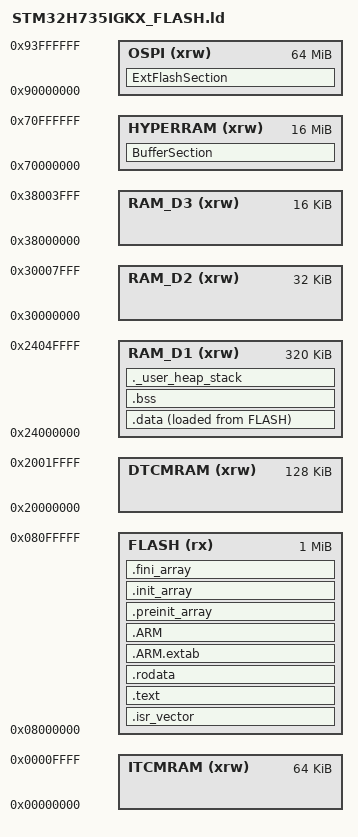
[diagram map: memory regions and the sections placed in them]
/**
 ******************************************************************************
 * @file      LinkerScript.ld
 * @author    Auto-generated by STM32CubeIDE
 * @brief     Linker script for STM32H735IGKx Device from STM32H7 series
 *                      1024Kbytes FLASH
 *                      128Kbytes DTCMRAM
 *                      64Kbytes ITCMRAM
 *                      320Kbytes RAM_D1
 *                      32Kbytes RAM_D2
 *                      16Kbytes RAM_D3
 *
 *            Set heap size, stack size and stack location according
 *            to application requirements.
 *
 *            Set memory bank area and size if external memory is used
 ******************************************************************************
 * @attention
 *
 * <h2><center>&copy; Copyright (c) 2020 STMicroelectronics.
 * All rights reserved.</center></h2>
 *
 * This software component is licensed by ST under BSD 3-Clause license,
 * the "License"; You may not use this file except in compliance with the
 * License. You may obtain a copy of the License at:
 *                        opensource.org/licenses/BSD-3-Clause
 *
 ******************************************************************************
 */

/* Entry Point */
ENTRY(Reset_Handler)

/* Highest address of the user mode stack */
_estack = ORIGIN(RAM_D1) + LENGTH(RAM_D1);	/* end of "RAM_D1" Ram type memory */

_Min_Heap_Size = 0x1000;	/* required amount of heap  */
_Min_Stack_Size = 0x1000;	/* required amount of stack */

/* Memories definition */
MEMORY
{
  DTCMRAM    (xrw)    : ORIGIN = 0x20000000,   LENGTH = 128K
  ITCMRAM    (xrw)    : ORIGIN = 0x00000000,   LENGTH = 64K
  RAM_D1     (xrw)    : ORIGIN = 0x24000000,   LENGTH = 320K
  RAM_D2     (xrw)    : ORIGIN = 0x30000000,   LENGTH = 32K
  RAM_D3     (xrw)    : ORIGIN = 0x38000000,   LENGTH = 16K
  FLASH      (rx)     : ORIGIN = 0x8000000,    LENGTH = 1024K
  OSPI	     (xrw)    : ORIGIN = 0x90000000,   LENGTH = 64M
  HYPERRAM   (xrw)    : ORIGIN = 0x70000000,   LENGTH = 16M
}

/* Sections */
SECTIONS
{
  /* The startup code into "FLASH" Rom type memory */
  .isr_vector :
  {
    . = ALIGN(4);
    KEEP(*(.isr_vector)) /* Startup code */
    . = ALIGN(4);
  } >FLASH

  /* The program code and other data into "FLASH" Rom type memory */
  .text :
  {
    . = ALIGN(4);
    *(.text)           /* .text sections (code) */
    *(.text*)          /* .text* sections (code) */
    *(.glue_7)         /* glue arm to thumb code */
    *(.glue_7t)        /* glue thumb to arm code */
    *(.eh_frame)

    KEEP (*(.init))
    KEEP (*(.fini))

    . = ALIGN(4);
    _etext = .;        /* define a global symbols at end of code */
  } >FLASH

  /* Constant data into "FLASH" Rom type memory */
  .rodata :
  {
    . = ALIGN(4);
    *(.rodata)         /* .rodata sections (constants, strings, etc.) */
    *(.rodata*)        /* .rodata* sections (constants, strings, etc.) */
    . = ALIGN(4);
  } >FLASH

  .ARM.extab   : { 
    . = ALIGN(4);
    *(.ARM.extab* .gnu.linkonce.armextab.*)
    . = ALIGN(4);
  } >FLASH
  
  .ARM : {
    . = ALIGN(4);
    __exidx_start = .;
    *(.ARM.exidx*)
    __exidx_end = .;
    . = ALIGN(4);
  } >FLASH

  .preinit_array     :
  {
    . = ALIGN(4);
    PROVIDE_HIDDEN (__preinit_array_start = .);
    KEEP (*(.preinit_array*))
    PROVIDE_HIDDEN (__preinit_array_end = .);
    . = ALIGN(4);
  } >FLASH
  
  .init_array :
  {
    . = ALIGN(4);
    PROVIDE_HIDDEN (__init_array_start = .);
    KEEP (*(SORT(.init_array.*)))
    KEEP (*(.init_array*))
    PROVIDE_HIDDEN (__init_array_end = .);
    . = ALIGN(4);
  } >FLASH
  
  .fini_array :
  {
    . = ALIGN(4);
    PROVIDE_HIDDEN (__fini_array_start = .);
    KEEP (*(SORT(.fini_array.*)))
    KEEP (*(.fini_array*))
    PROVIDE_HIDDEN (__fini_array_end = .);
    . = ALIGN(4);
  } >FLASH

  /* Used by the startup to initialize data */
  _sidata = LOADADDR(.data);

  /* Initialized data sections into "RAM_D1" Ram type memory */
  .data : 
  {
    . = ALIGN(4);
    _sdata = .;        /* create a global symbol at data start */
    *(.data)           /* .data sections */
    *(.data*)          /* .data* sections */

    . = ALIGN(4);
    _edata = .;        /* define a global symbol at data end */
    
  } >RAM_D1 AT> FLASH

  /* Uninitialized data section into "RAM_D1" Ram type memory */
  . = ALIGN(4);
  .bss :
  {
    /* This is used by the startup in order to initialize the .bss section */
    _sbss = .;         /* define a global symbol at bss start */
    __bss_start__ = _sbss;
    *(.bss)
    *(.bss*)
    *(COMMON)

    . = ALIGN(4);
    _ebss = .;         /* define a global symbol at bss end */
    __bss_end__ = _ebss;
  } >RAM_D1

  /* User_heap_stack section, used to check that there is enough "RAM_D1" Ram  type memory left */
  ._user_heap_stack :
  {
    . = ALIGN(8);
    PROVIDE ( end = . );
    PROVIDE ( _end = . );
    . = . + _Min_Heap_Size;
    . = . + _Min_Stack_Size;
    . = ALIGN(8);
  } >RAM_D1

  /* Remove information from the compiler libraries */
  /DISCARD/ :
  {
    libc.a ( * )
    libm.a ( * )
    libgcc.a ( * )
  }

  .ARM.attributes 0 : { *(.ARM.attributes) }
/*
  FontFlashSection :
  {
    *(FontFlashSection FontFlashSection.*)
    *(.gnu.linkonce.r.*)
    . = ALIGN(0x4);
  } >OSPI

  TextFlashSection :
  {
    *(TextFlashSection TextFlashSection.*)
    *(.gnu.linkonce.r.*)
    . = ALIGN(0x4);
  } >OSPI
*/
  ExtFlashSection :
  {
    *(ExtFlashSection ExtFlashSection.*)
    *(.gnu.linkonce.r.*)
    . = ALIGN(0x4);
  } >OSPI
  
  BufferSection (NOLOAD) :
  {
	*(TouchGFX_Framebuffer TouchGFX_Framebuffer.*)
    *(.gnu.linkonce.r.*)
    . = ALIGN(0x4);
	
	*(Video_RGB_Buffer Video_RGB_Buffer.*)
    *(.gnu.linkonce.r.*)
    . = ALIGN(0x4);
        
    *(image_abs_detection_r_buf image_abs_detection_r_buf.*)
    *(.gnu.linkonce.r.*)
    . = ALIGN(0x4);
    
	*(image_abs_detection_w_buf image_abs_detection_w_buf.*)
	*(.gnu.linkonce.r.*)
    . = ALIGN(0x4);
    
    *(image_fuelicon_r_buf image_fuelicon_r_buf.*)
	*(.gnu.linkonce.r.*)
    . = ALIGN(0x4);
    
    *(image_fuelicon_w_buf image_fuelicon_w_buf.*)
	*(.gnu.linkonce.r.*)
    . = ALIGN(0x4);
    
    *(image_doorsicon_r_buf image_doorsicon_r_buf.*)
	*(.gnu.linkonce.r.*)
    . = ALIGN(0x4);
    
    *(image_doorsicon_w_buf image_doorsicon_w_buf.*)
	*(.gnu.linkonce.r.*)
    . = ALIGN(0x4);
    
    *(image_engineoil_r_buf image_engineoil_r_buf.*)
	*(.gnu.linkonce.r.*)
    . = ALIGN(0x4);
    
    *(image_engineoil_w_buf image_engineoil_w_buf.*)
	*(.gnu.linkonce.r.*)
    . = ALIGN(0x4);
    
    *(image_enginewarning_w_buf image_enginewarning_w_buf.*)
	*(.gnu.linkonce.r.*)
    . = ALIGN(0x4);
    
    *(image_enginewarning_y_buf image_enginewarning_y_buf.*)
	*(.gnu.linkonce.r.*)
    . = ALIGN(0x4);
    
    *(image_fuelbar01_buf image_fuelbar01_buf.*)
	*(.gnu.linkonce.r.*)
    . = ALIGN(0x4);
    
    *(image_fuelbar02_buf image_fuelbar02_buf.*)
	*(.gnu.linkonce.r.*)
    . = ALIGN(0x4);
    
    *(image_fuelbar03_buf image_fuelbar03_buf.*)
	*(.gnu.linkonce.r.*)
    . = ALIGN(0x4);
    
    *(image_fuelbar04_buf image_fuelbar04_buf.*)
	*(.gnu.linkonce.r.*)
    . = ALIGN(0x4);
    
    *(image_fuelbar05_buf image_fuelbar05_buf.*)
	*(.gnu.linkonce.r.*)
    . = ALIGN(0x4);
    
    *(image_fuelbar06_buf image_fuelbar06_buf.*)
	*(.gnu.linkonce.r.*)
    . = ALIGN(0x4);
    
    *(image_fuelbar07_buf image_fuelbar07_buf.*)
	*(.gnu.linkonce.r.*)
    . = ALIGN(0x4);
    
    *(image_fuelbar08_buf image_fuelbar08_buf.*)
	*(.gnu.linkonce.r.*)
    . = ALIGN(0x4);
    
    *(image_fuelbar09_buf image_fuelbar09_buf.*)
	*(.gnu.linkonce.r.*)
    . = ALIGN(0x4);
    
    *(image_fuelbar10_buf image_fuelbar10_buf.*)
	*(.gnu.linkonce.r.*)
    . = ALIGN(0x4);
    
     *(image_highbeam_blue_buf image_highbeam_blue_buf.*)
	*(.gnu.linkonce.r.*)
    . = ALIGN(0x4);
    
    *(image_highbeam_wb_buf image_highbeam_wb_buf.*)
	*(.gnu.linkonce.r.*)
    . = ALIGN(0x4);
    
    *(image_highbeam_r_buf image_highbeam_r_buf.*)
	*(.gnu.linkonce.r.*)
    . = ALIGN(0x4);
    
    *(image_highbeam_w_buf image_highbeam_w_buf.*)
	*(.gnu.linkonce.r.*)
    . = ALIGN(0x4);
    
    *(image_hmi_layout1_buf image_hmi_layout1_buf.*)
	*(.gnu.linkonce.r.*)
    . = ALIGN(0x4);
    
    *(image_leftindicator_r_buf image_leftindicator_r_buf.*)
	*(.gnu.linkonce.r.*)
    . = ALIGN(0x4);
    
    *(image_leftindicator_w_buf image_leftindicator_w_buf.*)
	*(.gnu.linkonce.r.*)
    . = ALIGN(0x4);
    
    *(image_lowbatteryicon_r_buf image_lowbatteryicon_r_buf.*)
	*(.gnu.linkonce.r.*)
    . = ALIGN(0x4);
    
    *(image_lowbatteryicon_w_buf image_lowbatteryicon_w_buf.*)
	*(.gnu.linkonce.r.*)
    . = ALIGN(0x4);
    
    *(image_lowbeam_r_buf image_lowbeam_r_buf.*)
	*(.gnu.linkonce.r.*)
    . = ALIGN(0x4);
    
    *(image_lowbeam_w_buf image_lowbeam_w_buf.*)
	*(.gnu.linkonce.r.*)
    . = ALIGN(0x4);
   
     *(image_parking_r_buf image_parking_r_buf.*)
	*(.gnu.linkonce.r.*)
    . = ALIGN(0x4);
    
     *(image_parking_w_buf image_parking__buf.*)
	*(.gnu.linkonce.r.*)
    . = ALIGN(0x4);
    
    *(image_rightindicator_r_buf image_rightindicator_r_buf.*)
	*(.gnu.linkonce.r.*)
    . = ALIGN(0x4);
    
    *(image_rightindicator_w_buf image_rightindicator_w_buf.*)
	*(.gnu.linkonce.r.*)
    . = ALIGN(0x4);
    
    *(image_rpmbar01_buf image_rpmbar01_buf.*)
	*(.gnu.linkonce.r.*)
    . = ALIGN(0x4);
    
    *(image_rpmbar02_buf image_rpmbar02_buf.*)
	*(.gnu.linkonce.r.*)
    . = ALIGN(0x4);
    
    *(image_rpmbar03_buf image_rpmbar03_buf.*)
	*(.gnu.linkonce.r.*)
    . = ALIGN(0x4);
    
    *(image_rpmbar04_buf image_rpmbar04_buf.*)
	*(.gnu.linkonce.r.*)
    . = ALIGN(0x4);
    
    *(image_rpmbar05_buf image_rpmbar05_buf.*)
	*(.gnu.linkonce.r.*)
    . = ALIGN(0x4);
    
    *(image_rpmbar06_buf image_rpmbar06_buf.*)
	*(.gnu.linkonce.r.*)
    . = ALIGN(0x4);
    
    *(image_rpmbar07_buf image_rpmbar07_buf.*)
	*(.gnu.linkonce.r.*)
    . = ALIGN(0x4);
    
    *(image_rpmbar08_buf image_rpmbar08_buf.*)
	*(.gnu.linkonce.r.*)
    . = ALIGN(0x4);
    
    *(image_rpmbar09_buf image_rpmbar09_buf.*)
	*(.gnu.linkonce.r.*)
    . = ALIGN(0x4);
    
    *(image_rpmbar10_buf image_rpmbar10_buf.*)
	*(.gnu.linkonce.r.*)
    . = ALIGN(0x4);
    
    *(image_rpmicon_r_buf image_rpmicon_r_buf.*)
	*(.gnu.linkonce.r.*)
    . = ALIGN(0x4);
    
    *(image_rpmicon_w_buf image_rpmicon_w_buf.*)
	*(.gnu.linkonce.r.*)
    . = ALIGN(0x4);
    
    *(image_seatbelt_r_buf image_seatbelt_r_buf.*)
	*(.gnu.linkonce.r.*)
    . = ALIGN(0x4);
    
    *(image_seatbelt_w_buf image_seatbelt_w_buf.*)
	*(.gnu.linkonce.r.*)
    . = ALIGN(0x4);
    
    *(image_servicereminder_w_buf image_servicereminder_w_buf.*)
	*(.gnu.linkonce.r.*)
    . = ALIGN(0x4);
    
    *(image_servicereminder_y_buf image_servicereminder_y_buf.*)
	*(.gnu.linkonce.r.*)
    . = ALIGN(0x4);
    
    *(image_temperature_r_buf image_temperature_r_buf.*)
	*(.gnu.linkonce.r.*)
    . = ALIGN(0x4);
    
    *(image_temperature_w_buf image_temperature_w_buf.*)
    *(.gnu.linkonce.r.*)
    . = ALIGN(0x4);
    
    *(image_background image_background_buf.*)
	*(.gnu.linkonce.r.*)
    . = ALIGN(0x4);
  } >HYPERRAM
}
